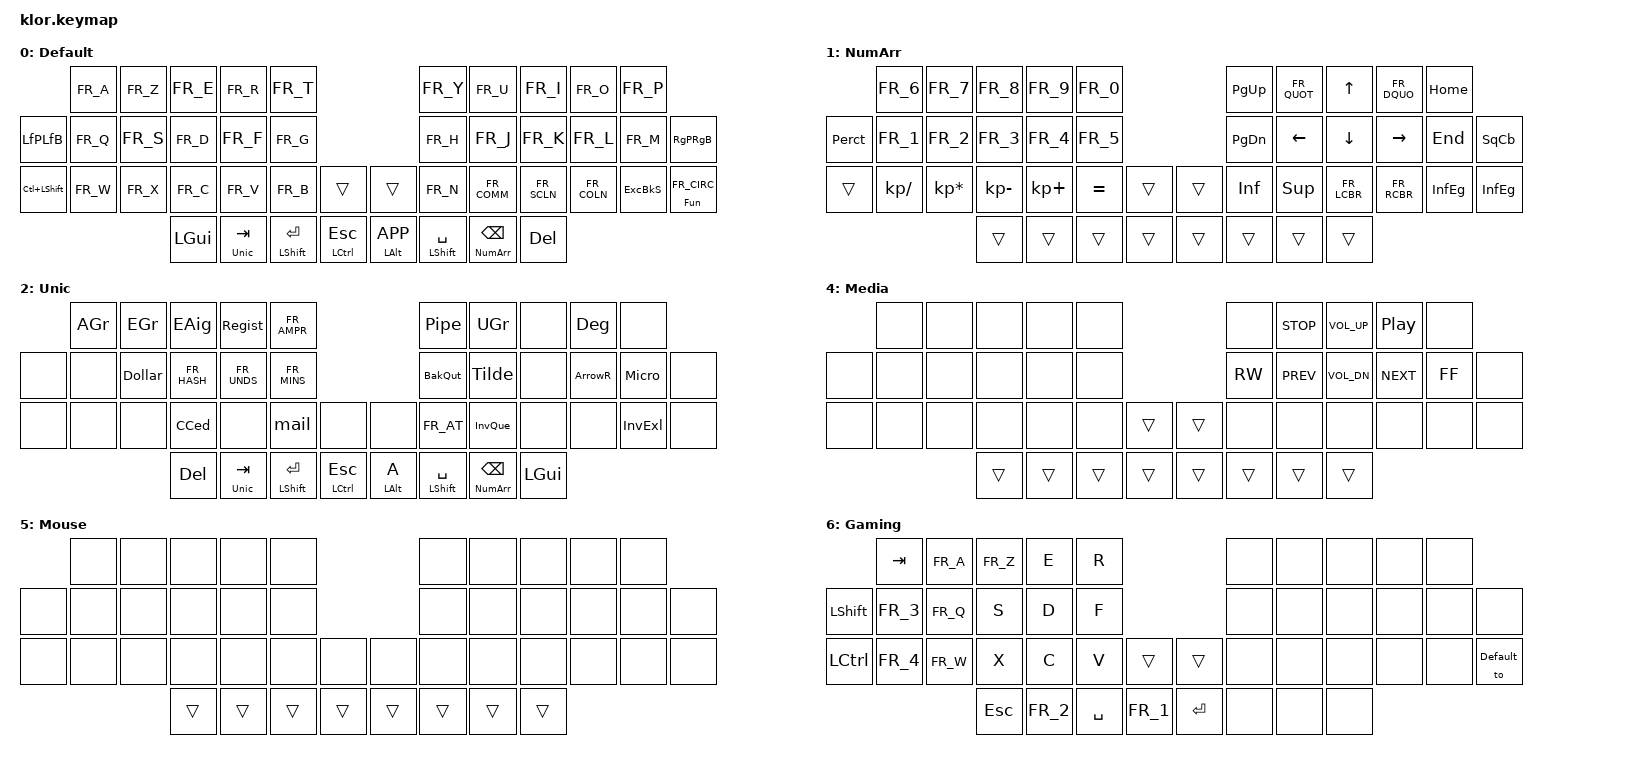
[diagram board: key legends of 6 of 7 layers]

//                               █         █    █            ▄▄▄▀▀▀▀▀▀▄▄▄        █▀▀▀▀▀▀▀▀▀▀█
//                               █        █     █          ▄▀            ▀▄      █          █
//                               █       █      █        ▄▀                ▀▄    █          █
//                               █      █       █        █                  █    █          █
//                               █     █        █       █                    █   █          █
//                               █    █         █       █                    █   █▄▄▄▄▄▄▄▄▄▄█
//                               █   █ █        █       █                    █   █      █
//                               █  █   █       █        █                  █    █       █
//                               █ █     █      █        ▀▄                ▄▀    █        █
//                               ██       █     █          ▀▄            ▄▀      █         █
//                               █         █    █▄▄▄▄▄▄▄▄    ▀▀▀▄▄▄▄▄▄▀▀▀        █          █
//
// ▄▄▄▄▄▄▄▄▄▄▄▄▄▄▄▄▄▄▄▄▄▄▄▄▄▄▄▄▄▄▄▄▄▄▄▄▄▄▄▄▄▄▄▄▄▄▄▄▄▄▄▄▄▄▄▄▄▄▄▄▄▄▄▄▄▄▄▄▄▄▄▄▄▄▄▄▄▄▄▄▄▄▄▄▄▄▄▄▄▄▄▄▄▄▄▄▄▄▄▄▄▄▄▄▄▄▄▄▄▄▄▄▄▄▄▄▄▄▄▄▄▄▄▄▄
       
#include <behaviors.dtsi>
#include <dt-bindings/zmk/keys.h>
#include <dt-bindings/zmk/bt.h>
#include <dt-bindings/zmk/outputs.h>
#include <dt-bindings/zmk/ext_power.h>
#include <dt-bindings/zmk/rgb.h>
#include "keymap_french.h"
#include "helper.h"
#include "french_unicode.dtsi"


#define Default   0
#define NumArr    1
#define Unic      2
#define Fun       3
#define Media     4
#define Mouse     5
#define Gaming    6


/ {
    behaviors {
              left_encoder_clw_alt: left_encoder_clw_alt {
                compatible = "zmk,behavior-mod-morph";
                bindings = <&kp C_VOL_DN>, <&kp LS(LA(TAB))>;
                #binding-cells = <0>;
                mods = <(MOD_LALT)>;
              };
              left_encoder_ccw_alt: left_encoder_ccw_alt {
                compatible = "zmk,behavior-mod-morph";
                bindings = <&kp C_VOL_UP>, <&kp LA(TAB)>;
                #binding-cells = <0>;
                mods = <(MOD_LALT)>;
              };
              left_encoder_kp: left_encoder_kp {
                compatible = "zmk,behavior-sensor-rotate";
                bindings = <&left_encoder_clw_alt>, <&left_encoder_ccw_alt>;
                #sensor-binding-cells = <0>;
              };

              right_encoder_clw_alt: right_encoder_clw_alt {
                compatible = "zmk,behavior-mod-morph";
                bindings = <&kp C_NEXT>, <&kp PG_UP>;
                #binding-cells = <0>;
                mods = <(MOD_LCTL)>;
              };
              right_encoder_ccw_alt: right_encoder_ccw_alt {
                compatible = "zmk,behavior-mod-morph";
                bindings = <&kp C_PREV>, <&kp PG_DN>;
                #binding-cells = <0>;
                mods = <(MOD_LCTL)>;
              };
              right_encoder_kp: right_encoder_kp {
                compatible = "zmk,behavior-sensor-rotate";
                bindings = <&right_encoder_clw_alt>, <&right_encoder_ccw_alt>;
                #sensor-binding-cells = <0>;
              };
    };

     combos {
            compatible = "zmk,combos";
            combo_esc {
                timeout-ms = <30>;
                key-positions = <0 1>;
                bindings = <&kp ESC>;
            };
            combo_ae {
                timeout-ms = <30>;
                key-positions = <0 2>;
                bindings = <&AE>;
            };
            combo_oe {
                timeout-ms = <30>;
                key-positions = <2 8>;
                bindings = <&OE>;
            };
    };

       macros {
              mail: mail {
                     compatible = "zmk,behavior-macro";
                     #binding-cells = <0>;
                     bindings = <&macro_tap &kp FR_Y &kp FR_O &kp FR_A &kp FR_N &kp FR_N &kp FR_DOT &kp FR_Y &kp FR_V &kp FR_I &kp FR_N &kp FR_AT &kp FR_E &kp FR_T &kp FR_I &kp FR_K &kp FR_DOT &kp FR_C &kp FR_O &kp FR_M>;
              };
       };

        keymap {
                compatible = "zmk,keymap";


// ▄▄▄▄▄▄▄▄▄▄▄▄▄▄▄▄▄▄▄▄▄▄▄▄▄▄▄▄▄▄▄▄▄▄▄▄▄▄▄▄▄▄▄▄▄▄▄▄▄▄▄▄▄▄▄▄▄▄▄▄▄▄▄▄▄▄▄▄▄▄▄▄▄▄▄▄▄▄▄▄▄▄▄▄▄▄▄▄▄▄▄▄▄▄▄▄▄▄▄▄▄▄▄▄▄▄▄▄▄▄▄▄▄▄▄▄▄▄▄▄▄▄▄▄▄▄▄▄▄▄▄▄▄▄▄▄▄▄▄▄▄▄


                Default_layer {
// ┌───────────────────────────────────────────────────────────┐
label= "Default"                                               ;
// └───────────────────────────────────────────────────────────┘
/*             ┌───────────┬───────────┬───────────┬───────────┬───────────┐                      ┌───────────┬───────────┬───────────┬───────────┬───────────┐
               │     A     │     Z     │     E     │     R     │     T     │                      │     Y     │     U     │     I     │     O     │     P     │
   ┌───────────┼───────────┼───────────┼───────────┼───────────┼───────────┤                      ├───────────┼───────────┼───────────┼───────────┼───────────┼───────────┐
   │     (     │     Q     │     S     │     D     │     F     │     G     │                      │     H     │     J     │     K     │     L     │     M     │     )     │
   ├───────────┼───────────┼───────────┼───────────┼───────────┼───────────┤╭─────────╮╭─────────╮├───────────┼───────────┼───────────┼───────────┼───────────┼───────────┤
   │ CTRL SHFT │     W     │     X     │     C     │     V     │     B     ││         ││         ││     N     │     ,     │     ;     │     :     │     !     │     ^     │
   └───────────┴───────────┴───────────┼───────────┼───────────┼───────────┼╰─────────╯╰─────────╯┼───────────┼───────────┼───────────┼───────────┴───────────┴───────────┘
                                       │    DEL    │    TAB    │   SPACE   │   CTRL   ││   ALT    │   SPACE   │    BSPC   │    GUI    │
                                       └───────────┴───────────┴───────────┴──────────┘└──────────┴───────────┴───────────┴───────────┘ */
 bindings = <
 //╷             ╷             ╷             ╷            ╷            ╷            ╷            ╷╷            ╷            ╷            ╷            ╷            ╷            ╷            ╷
                  &kp FR_A      &kp FR_Z      &kp FR_E     &kp FR_R     &kp FR_T                                &kp FR_Y     &kp FR_U     &kp FR_I     &kp FR_O     &kp FR_P
    &LfPLfB       &kp FR_Q      &kp FR_S      &kp FR_D     &kp FR_F     &kp FR_G                                &kp FR_H     &kp FR_J     &kp FR_K     &kp FR_L     &kp FR_M     &RgPRgB
    &kp LC(LSHFT) &kp FR_W      &kp FR_X      &kp FR_C     &kp FR_V     &kp FR_B     &trans        &trans       &kp FR_N     &kp FR_COMM  &kp FR_SCLN  &kp FR_COLN  &ExcBkS      &lt Fun FR_CIRC
                                              &kp LGUI     &lt Unic TAB &mt LSHFT RET&mt LCTRL ESC&mt LALT K_APP&mt LSHFT SPACE&lt NumArr BSPC &kp DEL
                        >;
            sensor-bindings = <&left_encoder_kp &right_encoder_kp>;
};


// ▄▄▄▄▄▄▄▄▄▄▄▄▄▄▄▄▄▄▄▄▄▄▄▄▄▄▄▄▄▄▄▄▄▄▄▄▄▄▄▄▄▄▄▄▄▄▄▄▄▄▄▄▄▄▄▄▄▄▄▄▄▄▄▄▄▄▄▄▄▄▄▄▄▄▄▄▄▄▄▄▄▄▄▄▄▄▄▄▄▄▄▄▄▄▄▄▄▄▄▄▄▄▄▄▄▄▄▄▄▄▄▄▄▄▄▄▄▄▄▄▄▄▄▄▄▄▄▄▄▄▄▄▄▄▄▄▄▄▄▄▄▄


                NumArr_layer {
// ┌───────────────────────────────────────────────────────────┐
label= "NumArr"                                                ;
// └───────────────────────────────────────────────────────────┘
/*             ┌───────────┬───────────┬───────────┬───────────┬───────────┐                      ┌───────────┬───────────┬───────────┬───────────┬───────────┐
               │     6     │     7     │     8     │     9     │     0     │                      │   PG_UP   │   QUOT    │     UP    │    DQUO   │   HOME    │
   ┌───────────┼───────────┼───────────┼───────────┼───────────┼───────────┤                      ├───────────┼───────────┼───────────┼───────────┼───────────┼───────────┐
   │     %     │     1     │     2     │     3     │     4     │     5     │                      │   PG_DN   │    LEFT   │    DOWN   │   RIGHT   │    END    │    ² ³    │
   ├───────────┼───────────┼───────────┼───────────┼───────────┼───────────┤╭─────────╮╭─────────╮├───────────┼───────────┼───────────┼───────────┼───────────┼───────────┤
   │           │     /     │     *     │     -     │     +     │     =     ││         ││         ││     [     │     ]     │     {     │     }     │     <     │     >     │
   └───────────┴───────────┴───────────┼───────────┼───────────┼───────────┼╰─────────╯╰─────────╯┼───────────┼───────────┼───────────┼───────────┴───────────┴───────────┘
                                       │           │           │           │          ││          │           │           │           │
                                       └───────────┴───────────┴───────────┴──────────┘└──────────┴───────────┴───────────┴───────────┘ */
 bindings = <
 //╷            ╷            ╷            ╷            ╷            ╷            ╷            ╷╷            ╷            ╷            ╷            ╷            ╷            ╷            ╷
                 &kp FR_6     &kp FR_7     &kp FR_8     &kp FR_9     &kp FR_0                                &kp PG_UP    &kp FR_QUOT  &kp UP       &kp FR_DQUO  &kp HOME
    &Perct       &kp FR_1     &kp FR_2     &kp FR_3     &kp FR_4     &kp FR_5                                &kp PG_DN    &kp LEFT     &kp DOWN     &kp RIGHT    &kp END      &SqCb
    &trans      &kp KP_DIVIDE&kp KP_MULTIPLY&kp KP_MINUS&kp KP_PLUS  &kp EQUAL    &trans        &trans       &Inf         &Sup         &kp FR_LCBR  &kp FR_RCBR  &InfEg       &InfEg
                                           &trans       &trans       &trans       &trans        &trans       &trans       &trans       &trans 
                        >;
            sensor-bindings = <&left_encoder_kp &right_encoder_kp>;
                };


// ▄▄▄▄▄▄▄▄▄▄▄▄▄▄▄▄▄▄▄▄▄▄▄▄▄▄▄▄▄▄▄▄▄▄▄▄▄▄▄▄▄▄▄▄▄▄▄▄▄▄▄▄▄▄▄▄▄▄▄▄▄▄▄▄▄▄▄▄▄▄▄▄▄▄▄▄▄▄▄▄▄▄▄▄▄▄▄▄▄▄▄▄▄▄▄▄▄▄▄▄▄▄▄▄▄▄▄▄▄▄▄▄▄▄▄▄▄▄▄▄▄▄▄▄▄▄▄▄▄▄▄▄▄▄▄▄▄▄▄▄▄▄


                Unic_layer {
// ┌───────────────────────────────────────────────────────────┐
label= "Unic"                                                  ;
// └───────────────────────────────────────────────────────────┘
/*             ┌───────────┬───────────┬───────────┬───────────┬───────────┐                      ┌───────────┬───────────┬───────────┬───────────┬───────────┐
               │     À     │     è     │     É     │     ®     │     &     │                      │     |     │     ù     │           │           │           │
   ┌───────────┼───────────┼───────────┼───────────┼───────────┼───────────┤                      ├───────────┼───────────┼───────────┼───────────┼───────────┼───────────┐
   │           │           │     $     │     #     │     _     │     -     │                      │     `     │     ~     │           │     →     │     µ     │           │
   ├───────────┼───────────┼───────────┼───────────┼───────────┼───────────┤╭─────────╮╭─────────╮├───────────┼───────────┼───────────┼───────────┼───────────┼───────────┤
   │           │           │           │     Ç     │           │   Mail    ││         ││         ││     @     │     ¿     │           │           │     ¡     │           │
   └───────────┴───────────┴───────────┼───────────┼───────────┼───────────┼╰─────────╯╰─────────╯┼───────────┼───────────┼───────────┼───────────┴───────────┴───────────┘
                                       │           │           │           │          ││          │   Alt Gr  │           │           │
                                       └───────────┴───────────┴───────────┴──────────┘└──────────┴───────────┴───────────┴───────────┘ */
 bindings = <
 //╷            ╷            ╷            ╷            ╷            ╷            ╷            ╷╷            ╷            ╷            ╷            ╷            ╷            ╷            ╷
                 &AGr         &EGr         &EAig        &Regist      &kp FR_AMPR                             &Pipe        &UGr         &none        &Deg         &none
    &none        &none        &Dollar      &kp FR_HASH  &kp FR_UNDS  &kp FR_MINS                             &BakQut      &Tilde       &none        &ArrowR      &Micro       &none
    &none        &none        &none        &CCed        &none        &mail        &none         &none        &kp FR_AT       &InvQue      &none        &none        &InvExl      &none
                                           &kp DEL      &lt Unic TAB &mt LSHFT RET &mt LCTRL ESC &mt LALT A &mt LSHFT SPACE &lt NumArr BSPC &kp LGUI
                        >;
            sensor-bindings = <&left_encoder_kp &right_encoder_kp>;
                };


// ▄▄▄▄▄▄▄▄▄▄▄▄▄▄▄▄▄▄▄▄▄▄▄▄▄▄▄▄▄▄▄▄▄▄▄▄▄▄▄▄▄▄▄▄▄▄▄▄▄▄▄▄▄▄▄▄▄▄▄▄▄▄▄▄▄▄▄▄▄▄▄▄▄▄▄▄▄▄▄▄▄▄▄▄▄▄▄▄▄▄▄▄▄▄▄▄▄▄▄▄▄▄▄▄▄▄▄▄▄▄▄▄▄▄▄▄▄▄▄▄▄▄▄▄▄▄▄▄▄▄▄▄▄▄▄▄▄▄▄▄▄▄


                Fun_layer {
// ┌───────────────────────────────────────────────────────────┐
label= "Fun"                                                   ;
// └───────────────────────────────────────────────────────────┘
/*             ┌───────────┬───────────┬───────────┬───────────┬───────────┐                      ┌───────────┬───────────┬───────────┬───────────┬───────────┐
               │    F1     │    F2     │    F3     │    F4     │           │                      │           │           │           │           │           │
   ┌───────────┼───────────┼───────────┼───────────┼───────────┼───────────┤                      ├───────────┼───────────┼───────────┼───────────┼───────────┼───────────┐
   │           │    F5     │    F6     │    F7     │    F8     │           │                      │   BT 0    │   BT 1    │   BT 2    │   BT 3    │   BT 4    │           │
   ├───────────┼───────────┼───────────┼───────────┼───────────┼───────────┤╭─────────╮╭─────────╮├───────────┼───────────┼───────────┼───────────┼───────────┼───────────┤
   │   Gaming  │    F9     │    F10    │    F11    │    F12    │           ││         ││         ││           │           │           │           │ BT Clear  │           │
   └───────────┴───────────┴───────────┼───────────┼───────────┼───────────┼╰─────────╯╰─────────╯┼───────────┼───────────┼───────────┼───────────┴───────────┴───────────┘
                                       │           │           │           │          ││          │           │           │           │
                                       └───────────┴───────────┴───────────┴──────────┘└──────────┴───────────┴───────────┴───────────┘ */
 bindings = <
 //╷             ╷             ╷             ╷             ╷             ╷             ╷             ╷╷             ╷             ╷             ╷             ╷            ╷            ╷            ╷
                  &kp F1        &kp F2        &kp F3        &kp F4        &none                                      &none         &none         &kp C_PP      &none        &none
    &trans        &kp F5        &kp F6        &kp F7        &kp F8        &none                                      &bt BT_SEL 0  &bt BT_SEL 1  &bt BT_SEL 2  &bt BT_SEL 3 &bt BT_SEL 4 &trans
    &to Gaming    &kp F9        &kp F10       &kp F11       &kp F12       &none         &trans         &trans       &kp LC(LS(ESC))&kp LA(F4)   &kp LC(LA(DEL))&none        &none        &bt BT_CLR   &trans
                                              &trans        &trans        &trans        &trans         &trans        &trans        &trans        &trans 
                        >;
            sensor-bindings = <&left_encoder_kp &right_encoder_kp>;
                };


// ▄▄▄▄▄▄▄▄▄▄▄▄▄▄▄▄▄▄▄▄▄▄▄▄▄▄▄▄▄▄▄▄▄▄▄▄▄▄▄▄▄▄▄▄▄▄▄▄▄▄▄▄▄▄▄▄▄▄▄▄▄▄▄▄▄▄▄▄▄▄▄▄▄▄▄▄▄▄▄▄▄▄▄▄▄▄▄▄▄▄▄▄▄▄▄▄▄▄▄▄▄▄▄▄▄▄▄▄▄▄▄▄▄▄▄▄▄▄▄▄▄▄▄▄▄▄▄▄▄▄▄▄▄▄▄▄▄▄▄▄▄▄


                Media_layer {
// ┌───────────────────────────────────────────────────────────┐
label= "Media"                                                 ;
// └───────────────────────────────────────────────────────────┘
/*             ┌───────────┬───────────┬───────────┬───────────┬───────────┐                      ┌───────────┬───────────┬───────────┬───────────┬───────────┐
               │           │           │           │           │           │                      │           │    ⏹︎	  │    ⏶︎	  │    ⏯︎	  │           │
   ┌───────────┼───────────┼───────────┼───────────┼───────────┼───────────┤                      ├───────────┼───────────┼───────────┼───────────┼───────────┼───────────┐
   │           │           │           │           │           │           │                      │    ⏪︎	  │    ⏮︎	  │    ⏷︎	  │    ⏭︎	  │    ⏩︎	  │           │
   ├───────────┼───────────┼───────────┼───────────┼───────────┼───────────┤╭─────────╮╭─────────╮├───────────┼───────────┼───────────┼───────────┼───────────┼───────────┤
   │           │           │           │           │           │           ││         ││         ││           │           │           │           │           │           │
   └───────────┴───────────┴───────────┼───────────┼───────────┼───────────┼╰─────────╯╰─────────╯┼───────────┼───────────┼───────────┼───────────┴───────────┴───────────┘
                                       │           │           │           │          ││          │           │           │           │
                                       └───────────┴───────────┴───────────┴──────────┘└──────────┴───────────┴───────────┴───────────┘ */
 bindings = <
 //╷            ╷            ╷            ╷            ╷            ╷            ╷            ╷╷            ╷            ╷            ╷            ╷            ╷            ╷            ╷
                 &none        &none        &none        &none        &none                                   &none        &kp C_STOP   &kp C_VOL_UP &kp C_PP     &none
    &none        &none        &none        &none        &none        &none                                   &kp C_RW     &kp C_PREV   &kp C_VOL_DN &kp C_NEXT   &kp C_FF     &none
    &none        &none        &none        &none        &none        &none        &trans        &trans       &none        &none        &none        &none        &none        &none
                                           &trans       &trans       &trans       &trans        &trans       &trans       &trans       &trans 
                        >;
            sensor-bindings = <&left_encoder_kp &right_encoder_kp>;
                };


// ▄▄▄▄▄▄▄▄▄▄▄▄▄▄▄▄▄▄▄▄▄▄▄▄▄▄▄▄▄▄▄▄▄▄▄▄▄▄▄▄▄▄▄▄▄▄▄▄▄▄▄▄▄▄▄▄▄▄▄▄▄▄▄▄▄▄▄▄▄▄▄▄▄▄▄▄▄▄▄▄▄▄▄▄▄▄▄▄▄▄▄▄▄▄▄▄▄▄▄▄▄▄▄▄▄▄▄▄▄▄▄▄▄▄▄▄▄▄▄▄▄▄▄▄▄▄▄▄▄▄▄▄▄▄▄▄▄▄▄▄▄▄


                Mouse_layer {
// ┌───────────────────────────────────────────────────────────┐
label= "Mouse"                                                 ;
// └───────────────────────────────────────────────────────────┘
/*             ┌───────────┬───────────┬───────────┬───────────┬───────────┐                      ┌───────────┬───────────┬───────────┬───────────┬───────────┐
               │           │           │           │           │           │                      │           │           │           │           │           │
   ┌───────────┼───────────┼───────────┼───────────┼───────────┼───────────┤                      ├───────────┼───────────┼───────────┼───────────┼───────────┼───────────┐
   │           │           │           │           │           │           │                      │           │           │           │           │           │           │
   ├───────────┼───────────┼───────────┼───────────┼───────────┼───────────┤╭─────────╮╭─────────╮├───────────┼───────────┼───────────┼───────────┼───────────┼───────────┤
   │           │           │           │           │           │           ││         ││         ││           │           │           │           │           │           │
   └───────────┴───────────┴───────────┼───────────┼───────────┼───────────┼╰─────────╯╰─────────╯┼───────────┼───────────┼───────────┼───────────┴───────────┴───────────┘
                                       │           │           │           │          ││          │           │           │           │
                                       └───────────┴───────────┴───────────┴──────────┘└──────────┴───────────┴───────────┴───────────┘ */
 bindings = <
 //╷            ╷            ╷            ╷            ╷            ╷            ╷            ╷╷            ╷            ╷            ╷            ╷            ╷            ╷            ╷
                 &none        &none        &none        &none        &none                                   &none        &none        &none        &none        &none
    &none        &none        &none        &none        &none        &none                                   &none        &none        &none        &none        &none        &none
    &none        &none        &none        &none        &none        &none        &none         &none        &none        &none        &none        &none        &none        &none
                                           &trans       &trans       &trans       &trans        &trans       &trans       &trans       &trans 
                        >;
            sensor-bindings = <&left_encoder_kp &right_encoder_kp>;
                };


// ▄▄▄▄▄▄▄▄▄▄▄▄▄▄▄▄▄▄▄▄▄▄▄▄▄▄▄▄▄▄▄▄▄▄▄▄▄▄▄▄▄▄▄▄▄▄▄▄▄▄▄▄▄▄▄▄▄▄▄▄▄▄▄▄▄▄▄▄▄▄▄▄▄▄▄▄▄▄▄▄▄▄▄▄▄▄▄▄▄▄▄▄▄▄▄▄▄▄▄▄▄▄▄▄▄▄▄▄▄▄▄▄▄▄▄▄▄▄▄▄▄▄▄▄▄▄▄▄▄▄▄▄▄▄▄▄▄▄▄▄▄▄


                Gaming_layer {
// ┌───────────────────────────────────────────────────────────┐
label= "Gaming"                                                ;
// └───────────────────────────────────────────────────────────┘
/*             ┌───────────┬───────────┬───────────┬───────────┬───────────┐                      ┌───────────┬───────────┬───────────┬───────────┬───────────┐
               │     Q     │     W     │     E     │     R     │     T     │                      │           │           │           │           │           │
   ┌───────────┼───────────┼───────────┼───────────┼───────────┼───────────┤                      ├───────────┼───────────┼───────────┼───────────┼───────────┼───────────┐
   │    TAB    │     A     │     S     │     D     │     F     │     G     │                      │           │           │           │           │           │           │
   ├───────────┼───────────┼───────────┼───────────┼───────────┼───────────┤╭─────────╮╭─────────╮├───────────┼───────────┼───────────┼───────────┼───────────┼───────────┤
   │    DEL    │     Z     │     X     │     C     │     V     │     B     ││         ││         ││           │           │           │           │           │           │
   └───────────┴───────────┴───────────┼───────────┼───────────┼───────────┼╰─────────╯╰─────────╯┼───────────┼───────────┼───────────┼───────────┴───────────┴───────────┘
                                       │    ESC    │     2     │   SPACE   │    1     ││  ENTER   │  Default  │           │           │
                                       └───────────┴───────────┴───────────┴──────────┘└──────────┴───────────┴───────────┴───────────┘ */
 bindings = <
 //╷            ╷            ╷            ╷            ╷            ╷            ╷            ╷╷            ╷            ╷            ╷            ╷            ╷            ╷            ╷
                 &kp TAB      &kp FR_A     &kp FR_Z     &kp E        &kp R                                   &none        &none        &none        &none        &none
    &kp LSHFT    &kp FR_3     &kp FR_Q     &kp S        &kp D        &kp F                                   &none        &none        &none        &none        &none        &none
    &kp LCTRL    &kp FR_4     &kp FR_W     &kp X        &kp C        &kp V        &trans        &trans       &none        &none        &none        &none        &none        &to Default
                                           &kp ESC      &kp FR_2     &kp SPACE    &kp FR_1      &kp RET      &none        &none        &none
                        >;
            sensor-bindings = <&left_encoder_kp &right_encoder_kp>;
                };

        };
};
